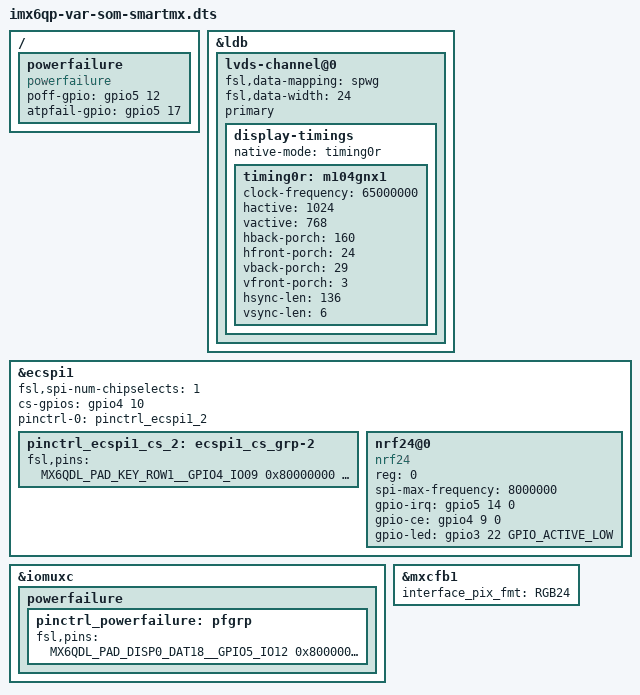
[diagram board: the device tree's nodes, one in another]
/*
 * Copyright (C) 2015-2017 Variscite Ltd.
 *
 * This program is free software; you can redistribute it and/or modify
 * it under the terms of the GNU General Public License version 2 as
 * published by the Free Software Foundation.
 */

#include "imx6qp-var-som.dtsi"

&ldb {
	status = "okay";

	lvds-channel@0 {
		fsl,data-mapping = "spwg";
		fsl,data-width = <24>;
		status = "okay";
		primary;

		display-timings {
			native-mode = <&timing0r>;
			timing0r: m104gnx1 {
				clock-frequency = <65000000>;
				hactive = <1024>;
				vactive = <768>;
				hback-porch = <160>;
				hfront-porch = <24>;
				vback-porch = <29>;
				vfront-porch = <3>;
				hsync-len = <136>;
				vsync-len = <6>;
			};
		};
	};

};

/* nRF24L01+ */
&ecspi1 {
	fsl,spi-num-chipselects = <1>;
	cs-gpios = <&gpio4 10 0>;
	pinctrl-names = "default";
	pinctrl-0 = <&pinctrl_ecspi1_2>;
	status = "okay";

	pinctrl_ecspi1_cs_2: ecspi1_cs_grp-2 {
		fsl,pins = <
                MX6QDL_PAD_KEY_ROW1__GPIO4_IO09                 0x80000000 /* nRF24L01+ CE  pin */
                MX6QDL_PAD_KEY_COL2__GPIO4_IO10                 0x80000000 /* SPI1_CS1 */
                MX6QDL_PAD_DISP0_DAT20__GPIO5_IO14              0x80000000 /* nRF24L01+ IRQ pin */
		MX6QDL_PAD_EIM_D22__GPIO3_IO22                  0x80000000
		>;
	};

        nrf24@0 {
                compatible = "nrf24";
                #address-cells = <1>;
                #size-cells = <0>;
                reg = <0>;
                spi-max-frequency = <8000000>;
                gpio-irq = <&gpio5 14 0>;
                gpio-ce  = <&gpio4 9 0>;
		gpio-led = <&gpio3 22 GPIO_ACTIVE_LOW>;
        };
};

&iomuxc {
        /* Power failure */
        powerfailure {
                pinctrl_powerfailure: pfgrp {
                        fsl,pins = <
                        MX6QDL_PAD_DISP0_DAT18__GPIO5_IO12              0x80000000
                        MX6QDL_PAD_DISP0_DAT23__GPIO5_IO17              0x80000000
                        >;
                };
        };

};

/ {
        powerfailure {
                compatible = "powerfailure";
                poff-gpio  = <&gpio5 12 0>;
                atpfail-gpio   = <&gpio5 17 0>;
        };
};

&mxcfb1 {
	interface_pix_fmt = "RGB24";
};
